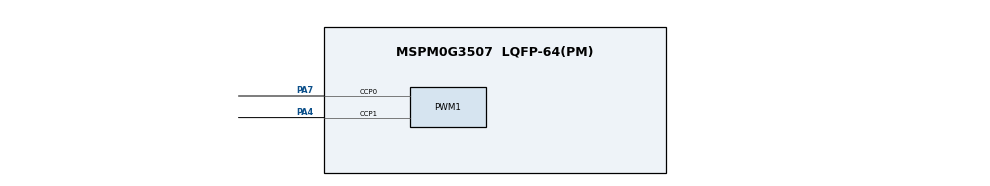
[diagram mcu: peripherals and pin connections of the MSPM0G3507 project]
/**
 * These arguments were used when this file was generated. They will be automatically applied on subsequent loads
 * via the GUI or CLI. Run CLI with '--help' for additional information on how to override these arguments.
 * @cliArgs --device "MSPM0G350X" --part "Default" --package "LQFP-64(PM)" --product "mspm0_sdk@2.10.00.04"
 * @v2CliArgs --device "MSPM0G3507" --package "LQFP-64(PM)" --product "mspm0_sdk@2.10.00.04"
 * @versions {"tool":"1.27.0+4565"}
 */

/**
 * Import the modules used in this configuration.
 */
const GPIO    = scripting.addModule("/ti/driverlib/GPIO", {}, false);
const GPIO1   = GPIO.addInstance();
const GPIO2   = GPIO.addInstance();
const GPIO3   = GPIO.addInstance();
const PWM     = scripting.addModule("/ti/driverlib/PWM", {}, false);
const PWM1    = PWM.addInstance();
const SYSCTL  = scripting.addModule("/ti/driverlib/SYSCTL");
const SYSTICK = scripting.addModule("/ti/driverlib/SYSTICK");

/**
 * Write custom configuration values to the imported modules.
 */
const divider6       = system.clockTree["PLL_CLK2X_DIV"];
divider6.divideValue = 4;

const divider7       = system.clockTree["PLL_PDIV"];
divider7.divideValue = 2;

const divider9       = system.clockTree["UDIV"];
divider9.divideValue = 2;

const multiplier2         = system.clockTree["PLL_QDIV"];
multiplier2.multiplyValue = 10;

const mux8       = system.clockTree["HSCLKMUX"];
mux8.inputSelect = "HSCLKMUX_SYSPLL2X";

GPIO1.$name                              = "GPIO_BEEP";
GPIO1.port                               = "PORTA";
GPIO1.associatedPins[0].$name            = "USER_BEEP";
GPIO1.associatedPins[0].assignedPin      = "27";
GPIO1.associatedPins[0].internalResistor = "PULL_DOWN";

const Board = scripting.addModule("/ti/driverlib/Board", {}, false);

GPIO2.$name                              = "GPIO_LEDS";
GPIO2.port                               = "PORTB";
GPIO2.associatedPins[0].$name            = "USER_LED_G";
GPIO2.associatedPins[0].assignedPin      = "27";
GPIO2.associatedPins[0].internalResistor = "PULL_DOWN";

GPIO3.$name                          = "GPIO_MOTOR_DIR";
GPIO3.associatedPins.create(2);
GPIO3.associatedPins[0].$name        = "MOTOR_A_DIR";
GPIO3.associatedPins[0].assignedPort = "PORTA";
GPIO3.associatedPins[0].assignedPin  = "3";
GPIO3.associatedPins[1].$name        = "MOTOR_B_DIR";
GPIO3.associatedPins[1].assignedPort = "PORTB";
GPIO3.associatedPins[1].assignedPin  = "14";

PWM1.clockDivider                       = 8;
PWM1.timerStartTimer                    = true;
PWM1.$name                              = "PWM_MOTOR";
PWM1.peripheral.ccp0Pin.$assign         = "PA7";
PWM1.peripheral.ccp1Pin.$assign         = "PA4";
PWM1.PWM_CHANNEL_0.$name                = "ti_driverlib_pwm_PWMTimerCC0";
PWM1.PWM_CHANNEL_0.invert               = true;
PWM1.PWM_CHANNEL_1.$name                = "ti_driverlib_pwm_PWMTimerCC1";
PWM1.PWM_CHANNEL_1.invert               = true;
PWM1.ccp0PinConfig.$name                = "ti_driverlib_gpio_GPIOPinGeneric0";
PWM1.ccp0PinConfig.direction            = scripting.forceWrite("OUTPUT");
PWM1.ccp0PinConfig.hideOutputInversion  = scripting.forceWrite(false);
PWM1.ccp0PinConfig.onlyInternalResistor = scripting.forceWrite(false);
PWM1.ccp0PinConfig.passedPeripheralType = scripting.forceWrite("Digital");
PWM1.ccp1PinConfig.$name                = "ti_driverlib_gpio_GPIOPinGeneric1";
PWM1.ccp1PinConfig.direction            = scripting.forceWrite("OUTPUT");
PWM1.ccp1PinConfig.hideOutputInversion  = scripting.forceWrite(false);
PWM1.ccp1PinConfig.onlyInternalResistor = scripting.forceWrite(false);
PWM1.ccp1PinConfig.passedPeripheralType = scripting.forceWrite("Digital");

SYSCTL.forceDefaultClkConfig = true;
SYSCTL.clockTreeEn           = true;

SYSTICK.periodEnable      = true;
SYSTICK.period            = 80000;
SYSTICK.interruptEnable   = true;
SYSTICK.interruptPriority = "0";
SYSTICK.systickEnable     = true;

/**
 * Pinmux solution for unlocked pins/peripherals. This ensures that minor changes to the automatic solver in a future
 * version of the tool will not impact the pinmux you originally saw.  These lines can be completely deleted in order to
 * re-solve from scratch.
 */
GPIO1.associatedPins[0].pin.$suggestSolution = "PA27";
Board.peripheral.$suggestSolution            = "DEBUGSS";
Board.peripheral.swclkPin.$suggestSolution   = "PA20";
Board.peripheral.swdioPin.$suggestSolution   = "PA19";
GPIO2.associatedPins[0].pin.$suggestSolution = "PB27";
GPIO3.associatedPins[0].pin.$suggestSolution = "PA3";
GPIO3.associatedPins[1].pin.$suggestSolution = "PB14";
PWM1.peripheral.$suggestSolution             = "TIMG8";
